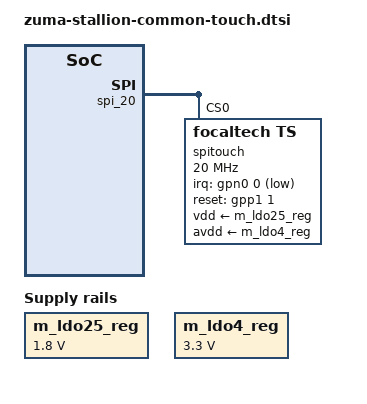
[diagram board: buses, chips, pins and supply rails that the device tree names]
// SPDX-License-Identifier: GPL-2.0-only
/*
 * Google stallion common touch device tree source
 *
 * Copyright 2024 Google LLC
 */

/* Touch is connected to spi_20, pins:
 *   CLK=GPB10[4], MOSI=GPB10[5], MISO=GPB10[6], CS=GPB10[7]
 * TS1_RESET_L = XAPC_USI11_RTSn_DI = GPP1[1] = <&gpp1 1 0>
 * TS1_INT_L = AOC_APM_TS1_INT_L_R1 / XAOC_GPIO0 = GPN0[0] = <&gpn0 0 0>
 *
 * DVDD = PP1800_L25M_TS1_DVDD = VLDO25M
 * AVDD = PP3300_L4M_TS1_AVDD  = VLDO4M
 */

#include <arm64/exynos/exynos-pinctrl.h>
#include <dt-bindings/regulator/samsung,s2mpg-regulator.h>

/ {
	fragment@touch_bus_negotiator {
		target-path = "/";
		__overlay__ {
			tbn: tbn {
				compatible = "touch_bus_negotiator";
				tbn,mode = <2>;
			};
		};
	};
};

&m_ldo25_reg {
	regulator-min-microvolt = <1800000>;
	regulator-max-microvolt = <1800000>;
};

&m_ldo4_reg {
	regulator-min-microvolt = <3300000>;
	regulator-max-microvolt = <3300000>;
};

/* GPIO_CUSTOM_ALIVE */
&pinctrl_1 {
	ts_irq: ts-irq {
		samsung,pins = "gpn0-0";
		samsung,pin-pud = <EXYNOS_PIN_PULL_NONE>;
		samsung,pin-drv = <ZUMA_PIN_DRV_X1>;
	};
};

&pinctrl_11 {
	ts_reset: ts-reset {
		samsung,pins = "gpp1-1";
		samsung,pin-pud = <EXYNOS_PIN_PULL_NONE>;
		samsung,pin-con-pdn = <EXYNOS_PIN_PDN_PREV>;
		samsung,pin-pud-pdn = <EXYNOS_PIN_PULL_NONE>;
	};
};

/* TODO: pinctrl for ts_spi_bus_active, ts_spi_cs_active,
 * ts_spi_bus_sleep, ts_spi_miso_sleep, ts_spi_cs_sleep
 */

&spi_20 {
	#address-cells = <1>;
	#size-cells = <0>;
	status = "okay";
	pinctrl-0 = <>; /* TODO: pinctrl */
	dma-mode;
	dmas = <&pdma1 18 &pdma1 19>;
	swap-mode = <1>;

	spitouch: touchscreen@0 {
		status = "ok";

		compatible = "focaltech,ts";
		reg = <0>;
		spi-max-frequency = <20000000>;

		pinctrl-names = "ts_active", "ts_suspend";
		pinctrl-0 = <&ts_irq &ts_reset>; /* TODO: pinctrl */
		pinctrl-1 = <>;

		vdd-supply = <&m_ldo25_reg>;
		avdd-supply = <&m_ldo4_reg>;

		focaltech,irq-gpio = <&gpn0 0 GPIO_ACTIVE_LOW>;
		focaltech,reset-gpio = <&gpp1 1 0>;
		focaltech,max-touch-number = <10>;
		focaltech,display-coords = <0 0 10800 24240>;
		focaltech,rx_ch_num = <36>;
		focaltech,tx_ch_num = <16>;

		focaltech,mm2px= /bits/ 8 <17>;

		goog,tbn-enabled;

		goog,panel_map = <&google_gs_staea 1>, <&google_gs_tg4b 1>, <&google_gs_tg4c 1>;
		goog,firmware_names = "focaltech_ts_fw.bin", "focaltech_ts_fw_b.bin";
		goog,test_limits_names = "focaltech_testconf.ini", "focaltech_testconf_b.ini";

		goog,touch_offload_id = /bits/ 8 <'s' 't' 'a' '5'>;
		goog,display-resolution = /bits/ 16 <1080 2424>;
		goog,channel-num = /bits/ 16 <16 36>;
		goog,offload-enabled;
		goog,v4l2-enabled;
		goog,offload-caps-data-types = /bits/ 16 <0x1F>;
		goog,offload-caps-scan-types = /bits/ 16 <0xC0>;
		goog,offload-caps-context-channel-types = /bits/ 16 <0x0100>;
		goog,lptw-suppress-coords-enabled;
		goog,lptw-tracking-area = <440 640 1656 1856>;
		goog,coord-filter-enabled;
		goog,offload-caps-coord-filter;
		goog,timestamp-correction-enabled;

		controller-data {
			samsung,spi-feedback-delay = <0>;
			samsung,spi-chip-select-mode = <0>;
		};
	};
};
